# S1C31D50 register map
Vendor: Epson; Series: S1C31D50; File version: 1.00
CPU: CM0PLUS r0p1, little endian, MPU, no FPU, VTOR, 2 interrupt priority bits
Registers are 16-bit, read-write, reset 0x0 unless marked. A register's access mark holds for its fields unless they carry their own. Offsets are from the block's base; [hi:lo] are bit positions; 'fields as' and 'values as' point back to an identical list.

## REMC3 — IR Remote Controller
Base 0x00200720
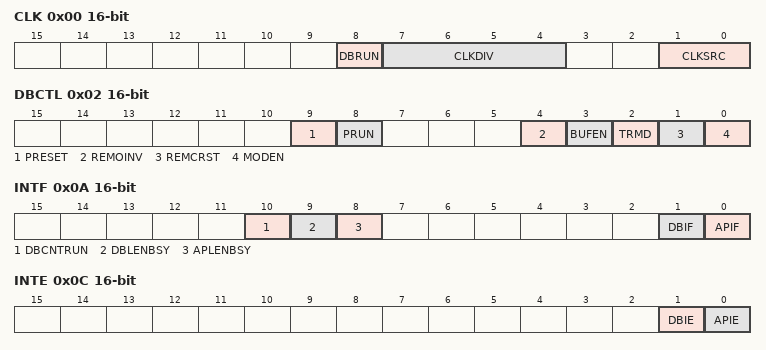
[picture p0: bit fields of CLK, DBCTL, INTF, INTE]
0x00 CLK — Clock Control Register
  [8] DBRUN — Enable clock on debug mode
    0=DISABLE; 1=ENABLE
  [7:4] CLKDIV — Clock division select
  [1:0] CLKSRC — Clock source select
    0=IOSC; 1=OSC1; 2=OSC3; 3=EXOSC
0x02 DBCTL — Data Bit Counter Control Register
  [9] PRESET write-1-sets — Data bit counter reset (Cleared by writing a 1 to this bit or writing to the REMCRST register bit)
    on write: 0=NON (No effect); 1=RESET | on read: 0=NORMAL (Resetting finished or normal operation); 1=BUSY (Resetting in progress)
  [8] PRUN — Data bit counter run/stop control (Cleared by writing a 1 to this bit or writing to the REMCRST register bit)
    on write: 0=STOP (Stop counting); 1=RUN (Start counting) | on read: 0=STOP (Idle); 1=RUN (Counting)
  [4] REMOINV — REMO invert
    0=NON_INVERT (Non-inverted); 1=INVERT (Inverted)
  [3] BUFEN — Buffer enable
    0=DISABLE; 1=ENABLE
  [2] TRMD — Data bit counter mode
    0=REPEAT (Repeat mode); 1=ONESHOT (One-shot mode)
  [1] REMCRST wo write-1-sets — Software Reset
    on write: 0=NON (No effect); 1=RESET (Issue software reset) | on read: 0=NORMAL (Software reset has finished (During normal operation)); 1=BUSY (Software reset is executing)
  [0] MODEN — REMC3 enable
    0=DISABLE; 1=ENABLE
0x04 DBCNT ro — Data Bit Counter Register (Cleared by writing to the REMCRST register bit)
  [15:0] DBCNT rw — The current value of the 16-bit counter for data signal generation can be read out through these bits.
0x06 APLEN — Data bit Active Pulse Length Register
  [15:0] APLEN — These bits set the active pulse length of the data signal(high period when the REMC3DBCTL.REMOINV bit = 0 or low period when the REMC3DBCTL.REMOINV bit = 1).
0x08 DBLEN — Data Bit Length Register
  [15:0] DBLEN — These bits set the data length of the data signal (length of one cycle).
0x0A INTF — Status / Interrupt Flag Register
  [10] DBCNTRUN ro — Data bit counter running status (Cleared by writing to the REMCRST)
    0=IDLE; 1=RUN (Running (Counting))
  [9] DBLENBSY ro — DBLEN buffer busy
    0=READY (Transfer to the DBLEN buffer has completed); 1=BUSY (Transfer to the DBLEN buffer has not completed)
  [8] APLENBSY ro — APLEN buffer busy
    0=READY (Transfer to the APLEN buffer has completed); 1=BUSY (Transfer to the APLEN buffer has not completed)
  [1] DBIF write-1-clears — Data bit length interrupt flag
    0=NOT_OCCURED (No cause of interrupt occurred); 1=OCCURED (Cause of interrupt occurred)
  [0] APIF write-1-clears — Data bit length first part interrupt flag (Cleared by writing to the REMCRST register bit or Cleared by writing 1)
    values as DBIF
0x0C INTE — Interrupt Enable Register
  [1] DBIE — Data bit length interrupt enable
    0=DISABLE; 1=ENABLE
  [0] APIE — Data bit length first part interrupt enable
    0=DISABLE; 1=ENABLE
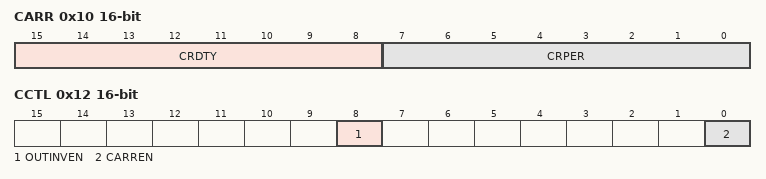
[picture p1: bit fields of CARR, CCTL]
0x10 CARR — Carrier Waveform Register
  [15:8] CRDTY — Carrier duty
  [7:0] CRPER — Carrier period
0x12 CCTL — Carrier Modulation Control Register
  [8] OUTINVEN — Output inversion enable
    0=NORMAL (Disable); 1=ENABLE (Inverted)
  [0] CARREN — Carrier modulation enable
    0=DISABLE; 1=ENABLE

## RFC_0
Base 0x00200840
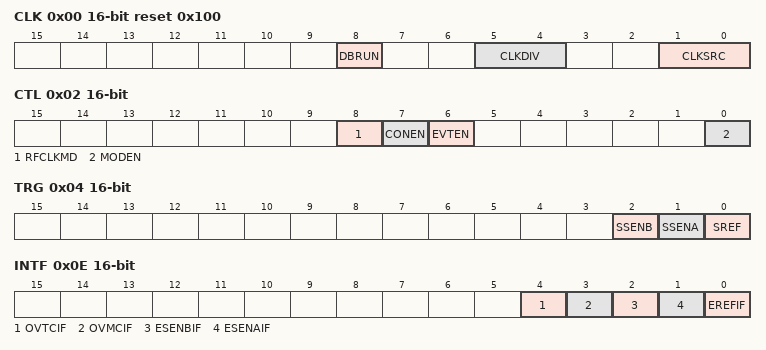
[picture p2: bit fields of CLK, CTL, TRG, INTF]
0x00 CLK reset 0x100 — Clock Control Register
  [8] DBRUN — Enable clock on debug mode
    0=DISABLE; 1=ENABLE
  [5:4] CLKDIV — Clock division select (can be write protected)
  [1:0] CLKSRC — TC clock source select (can be write protected)
    0=IOSC; 1=OSC1; 2=OSC3; 3=EXOSC
0x02 CTL — RFC Control Register
  [8] RFCLKMD — RFCLKO output mode select
    0=NORMAL; 1=1_2DIV (1/2 Divide)
  [7] CONEN — Continuous oscillation enable
    0=DISABLE (Disabled); 1=ENABLE (Enabled)
  [6] EVTEN — Event counter mode enable
    0=DISABLE (Disabled); 1=ENABLE (Enabled)
  [0] MODEN — RFC Module Enable
0x04 TRG — Oscillation Trigger Register
  [all] fields
    0=STOP (Stop Trigger); 1=START (Start Trigger)
  [2] SSENB — Sensor B oscillation start trigger
  [1] SSENA — Sensor A oscillation start trigger
  [0] SREF — Reference DC Oscillation Start Trigger
0x06 MCL — Measurement Counter Low Register
  [15:0] MC — MC[15:0] Measurement Counter data
0x08 MCH — Measurement Counter High Register
  [7:0] MC — MC[23:16] Measurement Counter data
0x0A TCL — Time Base Counter Low Register
  [15:0] TC — TC[15:0] Time Base Counter data
0x0C TCH — Time Base Counter High Register
  [7:0] TC — TC[23:16] Time Base Counter data
0x0E INTF — Interrupt Flag Register
  [all] fields
    0=NOT_OCCURED (No cause of interrupt occurred); 1=OCCURED (Cause of interrupt occurred)
  [4] OVTCIF write-1-clears — Time base Counter Overflow error Interrupt Flag
  [3] OVMCIF write-1-clears — Measurement Counter Overflow error Interrupt Flag
  [2] ESENBIF write-1-clears — Sensor B oscillation End Interrupt Flag
  [1] ESENAIF write-1-clears — Sensor A oscillation End Interrupt Flag
  [0] EREFIF write-1-clears — Reference oscillation End flag Interrupt Flag
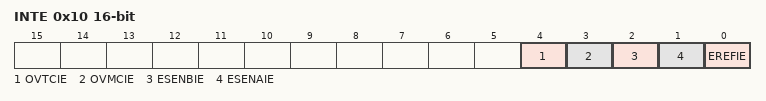
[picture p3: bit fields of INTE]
0x10 INTE — Interrupt Enable Register
  [all] fields
    0=DISABLE (Disabled); 1=ENABLE (Enabled)
  [4] OVTCIE — Time base Counter Overflow error Interrupt enable
  [3] OVMCIE — Measurement Counter Overflow error Interrupt enable
  [2] ESENBIE — Sensor B oscillation End Interrupt enable
  [1] ESENAIE — Sensor A oscillation End Interrupt enable
  [0] EREFIE — Reference oscillation End flag Interrupt enable
